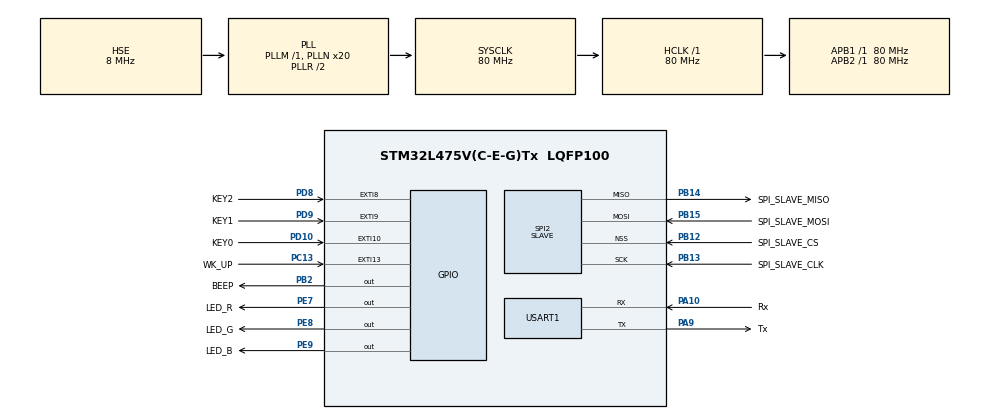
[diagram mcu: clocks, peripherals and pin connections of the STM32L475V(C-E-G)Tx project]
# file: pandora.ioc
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IWDG.Prescaler=IWDG_PRESCALER_64
IWDG.Reload=3000
IWDG.Window=2990
Mcu.Family=STM32L4
Mcu.Name=STM32L475V(C-E-G)Tx
Mcu.Package=LQFP100
NVIC.EXTI15_10_IRQn=true\:6\:0\:true\:false\:true\:true\:true
NVIC.EXTI9_5_IRQn=true\:6\:0\:true\:false\:true\:true\:true
NVIC.PriorityGroup=NVIC_PRIORITYGROUP_4
NVIC.TIM3_IRQn=true\:2\:0\:true\:false\:true\:true\:true
NVIC.USART1_IRQn=true\:3\:0\:true\:false\:false\:true\:false
PA10.GPIO_Label=Rx
PA10.Mode=Asynchronous
PA10.Signal=USART1_RX
PA9.GPIO_Label=Tx
PA9.Mode=Asynchronous
PA9.Signal=USART1_TX
PB12.GPIO_Label=SPI_SLAVE_CS
PB12.Mode=NSS_Signal_Hard_Input
PB12.Signal=SPI2_NSS
PB13.GPIO_Label=SPI_SLAVE_CLK
PB13.Mode=Full_Duplex_Slave
PB13.Signal=SPI2_SCK
PB14.GPIO_Label=SPI_SLAVE_MISO
PB14.Mode=Full_Duplex_Slave
PB14.Signal=SPI2_MISO
PB15.GPIO_Label=SPI_SLAVE_MOSI
PB15.Mode=Full_Duplex_Slave
PB15.Signal=SPI2_MOSI
PB2.GPIO_Label=BEEP
PB2.GPIO_PuPd=GPIO_PULLDOWN
PB2.Signal=GPIO_Output
PC13.GPIO_Label=WK_UP
PC13.GPIO_PuPd=GPIO_PULLDOWN
PC13.Signal=GPXTI13
PC14-OSC32_IN\ (PC14).Mode=LSE-External-Oscillator
PC14-OSC32_IN\ (PC14).Signal=RCC_OSC32_IN
PC15-OSC32_OUT\ (PC15).Mode=LSE-External-Oscillator
PC15-OSC32_OUT\ (PC15).Signal=RCC_OSC32_OUT
PD10.GPIO_Label=KEY0
PD10.GPIO_ModeDefaultEXTI=GPIO_MODE_IT_FALLING
PD10.GPIO_PuPd=GPIO_PULLUP
PD10.Signal=GPXTI10
PD8.GPIO_Label=KEY2
PD8.GPIO_ModeDefaultEXTI=GPIO_MODE_IT_FALLING
PD8.GPIO_PuPd=GPIO_PULLUP
PD8.Signal=GPXTI8
PD9.GPIO_Label=KEY1
PD9.GPIO_ModeDefaultEXTI=GPIO_MODE_IT_FALLING
PD9.GPIO_PuPd=GPIO_PULLUP
PD9.Signal=GPXTI9
PE7.GPIO_Label=LED_R
PE7.GPIO_PuPd=GPIO_PULLUP
PE7.PinState=GPIO_PIN_SET
PE7.Signal=GPIO_Output
PE8.GPIO_Label=LED_G
PE8.GPIO_PuPd=GPIO_PULLUP
PE8.GPIO_Speed=GPIO_SPEED_FREQ_LOW
PE8.PinState=GPIO_PIN_SET
PE8.Signal=GPIO_Output
PE9.GPIO_Label=LED_B
PE9.GPIO_PuPd=GPIO_PULLUP
PE9.PinState=GPIO_PIN_SET
PE9.Signal=GPIO_Output
PH0-OSC_IN\ (PH0).Mode=HSE-External-Oscillator
PH0-OSC_IN\ (PH0).Signal=RCC_OSC_IN
PH1-OSC_OUT\ (PH1).Mode=HSE-External-Oscillator
PH1-OSC_OUT\ (PH1).Signal=RCC_OSC_OUT
ProjectManager.HeapSize=0x200
ProjectManager.StackSize=0x400
ProjectManager.TargetToolchain=MDK-ARM V5
RCC.ADCFreq_Value=32000000
RCC.AHBFreq_Value=80000000
RCC.APB1Freq_Value=80000000
RCC.APB1TimFreq_Value=80000000
RCC.APB2Freq_Value=80000000
RCC.APB2TimFreq_Value=80000000
RCC.CortexFreq_Value=80000000
RCC.HCLKFreq_Value=80000000
RCC.HSE_VALUE=8000000
RCC.HSI_VALUE=16000000
RCC.MSI_VALUE=4000000
RCC.PLLN=20
RCC.PLLSourceVirtual=RCC_PLLSOURCE_HSE
RCC.SYSCLKFreq_VALUE=80000000
RCC.SYSCLKSource=RCC_SYSCLKSOURCE_PLLCLK
RCC.USBFreq_Value=32000000
RCC.VCOOutputFreq_Value=160000000
SPI2.CLKPhase=SPI_PHASE_2EDGE
SPI2.CLKPolarity=SPI_POLARITY_HIGH
SPI2.DataSize=SPI_DATASIZE_8BIT
SPI2.Direction=SPI_DIRECTION_2LINES
SPI2.Mode=SPI_MODE_SLAVE
SPI2.VirtualNSS=VM_NSSHARD
SPI2.VirtualType=VM_SLAVE
TIM3.Period=5000-1
TIM3.Prescaler=8000-1
USART1.VirtualMode-Asynchronous=VM_ASYNC
VP_IWDG_VS_IWDG.Mode=IWDG_Activate
VP_TIM3_VS_ClockSourceINT.Mode=Internal
board=custom

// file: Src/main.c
/* USER CODE BEGIN Header */
/**
  ******************************************************************************
  * @file           : main.c
  * @brief          : Main program body
  ******************************************************************************
  * @attention
  *
  * <h2><center>&copy; Copyright (c) 2019 STMicroelectronics.
  * All rights reserved.</center></h2>
  *
  * This software component is licensed by ST under BSD 3-Clause license,
  * the "License"; You may not use this file except in compliance with the
  * License. You may obtain a copy of the License at:
  *                        opensource.org/licenses/BSD-3-Clause
  *
  ******************************************************************************
  */
/* USER CODE END Header */

#include "main.h"

/* USER CODE BEGIN Includes */
#include "sysmngr.h"
/* USER CODE END Includes */

IWDG_HandleTypeDef hiwdg;

SPI_HandleTypeDef hspi2;

TIM_HandleTypeDef htim3;

UART_HandleTypeDef huart1;

void SystemClock_Config(void);
static void MX_GPIO_Init(void);
static void MX_USART1_UART_Init(void);
static void MX_IWDG_Init(void);
static void MX_SPI2_Init(void);
static void MX_TIM3_Init(void);

int main(void)
{

  /* MCU Configuration--------------------------------------------------------*/

  /* Reset of all peripherals, Initializes the Flash interface and the Systick. */
  HAL_Init();

  /* Configure the system clock */
  SystemClock_Config();

  /* Initialize all configured peripherals */
  MX_GPIO_Init();
  MX_USART1_UART_Init();
  MX_IWDG_Init();
  MX_SPI2_Init();
  MX_TIM3_Init();
  /* USER CODE BEGIN 2 */
  usr_system_init();
  /* USER CODE END 2 */

  /* Infinite loop */
  /* USER CODE BEGIN WHILE */
  while (1)
  {
    usr_system_ctrl_manager();
    //TODO: BUTTON Exit

    /* USER CODE END WHILE */

  }
}

void SystemClock_Config(void)
{
  RCC_OscInitTypeDef RCC_OscInitStruct = {0};
  RCC_ClkInitTypeDef RCC_ClkInitStruct = {0};
  RCC_PeriphCLKInitTypeDef PeriphClkInit = {0};

  /** Initializes the CPU, AHB and APB busses clocks
  */
  RCC_OscInitStruct.OscillatorType = RCC_OSCILLATORTYPE_LSI|RCC_OSCILLATORTYPE_HSE;
  RCC_OscInitStruct.HSEState = RCC_HSE_ON;
  RCC_OscInitStruct.LSIState = RCC_LSI_ON;
  RCC_OscInitStruct.PLL.PLLState = RCC_PLL_ON;
  RCC_OscInitStruct.PLL.PLLSource = RCC_PLLSOURCE_HSE;
  RCC_OscInitStruct.PLL.PLLM = 1;
  RCC_OscInitStruct.PLL.PLLN = 20;
  RCC_OscInitStruct.PLL.PLLP = RCC_PLLP_DIV7;
  RCC_OscInitStruct.PLL.PLLQ = RCC_PLLQ_DIV2;
  RCC_OscInitStruct.PLL.PLLR = RCC_PLLR_DIV2;
  if (HAL_RCC_OscConfig(&RCC_OscInitStruct) != HAL_OK)
  {
    Error_Handler();
  }
  /** Initializes the CPU, AHB and APB busses clocks
  */
  RCC_ClkInitStruct.ClockType = RCC_CLOCKTYPE_HCLK|RCC_CLOCKTYPE_SYSCLK
                              |RCC_CLOCKTYPE_PCLK1|RCC_CLOCKTYPE_PCLK2;
  RCC_ClkInitStruct.SYSCLKSource = RCC_SYSCLKSOURCE_PLLCLK;
  RCC_ClkInitStruct.AHBCLKDivider = RCC_SYSCLK_DIV1;
  RCC_ClkInitStruct.APB1CLKDivider = RCC_HCLK_DIV1;
  RCC_ClkInitStruct.APB2CLKDivider = RCC_HCLK_DIV1;

  if (HAL_RCC_ClockConfig(&RCC_ClkInitStruct, FLASH_LATENCY_4) != HAL_OK)
  {
    Error_Handler();
  }
  PeriphClkInit.PeriphClockSelection = RCC_PERIPHCLK_USART1;
  PeriphClkInit.Usart1ClockSelection = RCC_USART1CLKSOURCE_PCLK2;
  if (HAL_RCCEx_PeriphCLKConfig(&PeriphClkInit) != HAL_OK)
  {
    Error_Handler();
  }
  /** Configure the main internal regulator output voltage
  */
  if (HAL_PWREx_ControlVoltageScaling(PWR_REGULATOR_VOLTAGE_SCALE1) != HAL_OK)
  {
    Error_Handler();
  }
}

static void MX_IWDG_Init(void)
{

  hiwdg.Instance = IWDG;
  hiwdg.Init.Prescaler = IWDG_PRESCALER_64;
  hiwdg.Init.Window = 2990;
  hiwdg.Init.Reload = 3000;
  if (HAL_IWDG_Init(&hiwdg) != HAL_OK)
  {
    Error_Handler();
  }

}

static void MX_SPI2_Init(void)
{

  /* SPI2 parameter configuration*/
  hspi2.Instance = SPI2;
  hspi2.Init.Mode = SPI_MODE_SLAVE;
  hspi2.Init.Direction = SPI_DIRECTION_2LINES;
  hspi2.Init.DataSize = SPI_DATASIZE_8BIT;
  hspi2.Init.CLKPolarity = SPI_POLARITY_HIGH;
  hspi2.Init.CLKPhase = SPI_PHASE_2EDGE;
  hspi2.Init.NSS = SPI_NSS_HARD_INPUT;
  hspi2.Init.FirstBit = SPI_FIRSTBIT_MSB;
  hspi2.Init.TIMode = SPI_TIMODE_DISABLE;
  hspi2.Init.CRCCalculation = SPI_CRCCALCULATION_DISABLE;
  hspi2.Init.CRCPolynomial = 7;
  hspi2.Init.CRCLength = SPI_CRC_LENGTH_DATASIZE;
  hspi2.Init.NSSPMode = SPI_NSS_PULSE_DISABLE;
  if (HAL_SPI_Init(&hspi2) != HAL_OK)
  {
    Error_Handler();
  }

}

static void MX_TIM3_Init(void)
{

  TIM_ClockConfigTypeDef sClockSourceConfig = {0};
  TIM_MasterConfigTypeDef sMasterConfig = {0};

  htim3.Instance = TIM3;
  htim3.Init.Prescaler = 8000-1;
  htim3.Init.CounterMode = TIM_COUNTERMODE_UP;
  htim3.Init.Period = 5000-1;
  htim3.Init.ClockDivision = TIM_CLOCKDIVISION_DIV1;
  htim3.Init.AutoReloadPreload = TIM_AUTORELOAD_PRELOAD_DISABLE;
  if (HAL_TIM_Base_Init(&htim3) != HAL_OK)
  {
    Error_Handler();
  }
  sClockSourceConfig.ClockSource = TIM_CLOCKSOURCE_INTERNAL;
  if (HAL_TIM_ConfigClockSource(&htim3, &sClockSourceConfig) != HAL_OK)
  {
    Error_Handler();
  }
  sMasterConfig.MasterOutputTrigger = TIM_TRGO_RESET;
  sMasterConfig.MasterSlaveMode = TIM_MASTERSLAVEMODE_DISABLE;
  if (HAL_TIMEx_MasterConfigSynchronization(&htim3, &sMasterConfig) != HAL_OK)
  {
    Error_Handler();
  }

}

static void MX_USART1_UART_Init(void)
{

  huart1.Instance = USART1;
  huart1.Init.BaudRate = 115200;
  huart1.Init.WordLength = UART_WORDLENGTH_8B;
  huart1.Init.StopBits = UART_STOPBITS_1;
  huart1.Init.Parity = UART_PARITY_NONE;
  huart1.Init.Mode = UART_MODE_TX_RX;
  huart1.Init.HwFlowCtl = UART_HWCONTROL_NONE;
  huart1.Init.OverSampling = UART_OVERSAMPLING_16;
  huart1.Init.OneBitSampling = UART_ONE_BIT_SAMPLE_DISABLE;
  huart1.AdvancedInit.AdvFeatureInit = UART_ADVFEATURE_NO_INIT;
  if (HAL_UART_Init(&huart1) != HAL_OK)
  {
    Error_Handler();
  }
  /* USER CODE BEGIN USART1_Init 2 */
  //__HAL_UART_ENABLE_IT(&huart1, UART_IT_RXNE); //开启接收中断
  /* USER CODE END USART1_Init 2 */

}

static void MX_GPIO_Init(void)
{
  GPIO_InitTypeDef GPIO_InitStruct = {0};

  /* GPIO Ports Clock Enable */
  __HAL_RCC_GPIOC_CLK_ENABLE();
  __HAL_RCC_GPIOH_CLK_ENABLE();
  __HAL_RCC_GPIOB_CLK_ENABLE();
  __HAL_RCC_GPIOE_CLK_ENABLE();
  __HAL_RCC_GPIOD_CLK_ENABLE();
  __HAL_RCC_GPIOA_CLK_ENABLE();

  /*Configure GPIO pin Output Level */
  HAL_GPIO_WritePin(BEEP_GPIO_Port, BEEP_Pin, GPIO_PIN_RESET);

  /*Configure GPIO pin Output Level */
  HAL_GPIO_WritePin(GPIOE, LED_R_Pin|LED_G_Pin|LED_B_Pin, GPIO_PIN_SET);

  /*Configure GPIO pin : WK_UP_Pin */
  GPIO_InitStruct.Pin = WK_UP_Pin;
  GPIO_InitStruct.Mode = GPIO_MODE_IT_RISING;
  GPIO_InitStruct.Pull = GPIO_PULLDOWN;
  HAL_GPIO_Init(WK_UP_GPIO_Port, &GPIO_InitStruct);

  /*Configure GPIO pin : BEEP_Pin */
  GPIO_InitStruct.Pin = BEEP_Pin;
  GPIO_InitStruct.Mode = GPIO_MODE_OUTPUT_PP;
  GPIO_InitStruct.Pull = GPIO_PULLDOWN;
  GPIO_InitStruct.Speed = GPIO_SPEED_FREQ_LOW;
  HAL_GPIO_Init(BEEP_GPIO_Port, &GPIO_InitStruct);

  /*Configure GPIO pins : LED_R_Pin LED_G_Pin LED_B_Pin */
  GPIO_InitStruct.Pin = LED_R_Pin|LED_G_Pin|LED_B_Pin;
  GPIO_InitStruct.Mode = GPIO_MODE_OUTPUT_PP;
  GPIO_InitStruct.Pull = GPIO_PULLUP;
  GPIO_InitStruct.Speed = GPIO_SPEED_FREQ_LOW;
  HAL_GPIO_Init(GPIOE, &GPIO_InitStruct);

  /*Configure GPIO pins : KEY2_Pin KEY1_Pin KEY0_Pin */
  GPIO_InitStruct.Pin = KEY2_Pin|KEY1_Pin|KEY0_Pin;
  GPIO_InitStruct.Mode = GPIO_MODE_IT_FALLING;
  GPIO_InitStruct.Pull = GPIO_PULLUP;
  HAL_GPIO_Init(GPIOD, &GPIO_InitStruct);

  /* EXTI interrupt init*/
  HAL_NVIC_SetPriority(EXTI9_5_IRQn, 6, 0);
  HAL_NVIC_EnableIRQ(EXTI9_5_IRQn);

  HAL_NVIC_SetPriority(EXTI15_10_IRQn, 6, 0);
  HAL_NVIC_EnableIRQ(EXTI15_10_IRQn);

}

void Error_Handler(void)
{
}

/************************ (C) COPYRIGHT STMicroelectronics *****END OF FILE****/
